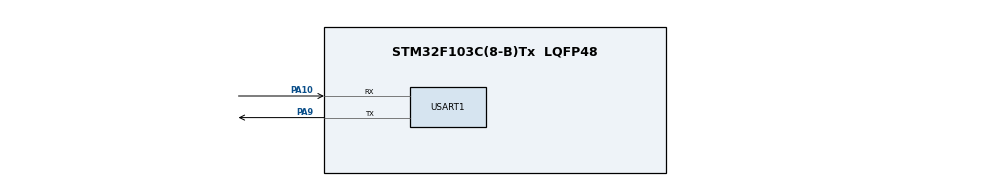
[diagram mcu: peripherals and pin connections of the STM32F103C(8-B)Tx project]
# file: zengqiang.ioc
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Mcu.Family=STM32F1
Mcu.Name=STM32F103C(8-B)Tx
Mcu.Package=LQFP48
NVIC.PriorityGroup=NVIC_PRIORITYGROUP_4
NVIC.USART1_IRQn=true\:0\:0\:false\:false\:true\:true\:true\:true
PA10.Mode=Asynchronous
PA10.Signal=USART1_RX
PA13.Mode=Serial_Wire
PA13.Signal=SYS_JTMS-SWDIO
PA14.Mode=Serial_Wire
PA14.Signal=SYS_JTCK-SWCLK
PA9.Mode=Asynchronous
PA9.Signal=USART1_TX
PD0-OSC_IN.Mode=HSE-External-Oscillator
PD0-OSC_IN.Signal=RCC_OSC_IN
PD1-OSC_OUT.Mode=HSE-External-Oscillator
PD1-OSC_OUT.Signal=RCC_OSC_OUT
ProjectManager.HeapSize=0x200
ProjectManager.StackSize=0x400
ProjectManager.TargetToolchain=MDK-ARM V5
RCC.APB1Freq_Value=8000000
RCC.APB2Freq_Value=8000000
USART1.VirtualMode=VM_ASYNC
board=custom

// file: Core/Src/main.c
/* USER CODE BEGIN Header */
/**
  ******************************************************************************
  * @file           : main.c
  * @brief          : Main program body
  ******************************************************************************
  * @attention
  *
  * Copyright (c) 2025 STMicroelectronics.
  * All rights reserved.
  *
  * This software is licensed under terms that can be found in the LICENSE file
  * in the root directory of this software component.
  * If no LICENSE file comes with this software, it is provided AS-IS.
  *
  ******************************************************************************
  */
/* USER CODE END Header */
#include "main.h"
#include "usart.h"
#include "gpio.h"

/* USER CODE BEGIN Includes */
#include <string.h>
/* USER CODE END Includes */

/* USER CODE BEGIN PD */
#define SEND_INTERVAL 500  // 发送间隔，单位ms
/* USER CODE END PD */

/* USER CODE BEGIN PV */
uint8_t send_enable = 1;  // 发送使能标志，1：允许发送，0：禁止发送
uint8_t rx_data;          // 接收缓冲区
uint8_t tx_buffer[] = "hello windows!\r\n";  // 要发送的字符串
/* USER CODE END PV */

void SystemClock_Config(void);
/* USER CODE BEGIN PFP */
void UART_Receive_Handler(void);
/* USER CODE END PFP */

/* USER CODE BEGIN 0 */
/**
  * @brief  串口接收中断处理函数
  * @param  None
  * @retval None
  */
void UART_Receive_Handler(void)
{
  // 根据接收到的字符控制发送状态
  switch(rx_data)
  {
    case '#':  // 暂停发送
      send_enable = 0;
      break;
    case '*':  // 继续发送
      send_enable = 1;
      break;
    default:   // 其他字符不处理
      break;
  }

  // 重新使能串口接收中断
  HAL_UART_Receive_IT(&huart1, &rx_data, 1);
}

/**
  * @brief  串口接收中断回调函数
  * @param  huart: 串口句柄
  * @retval None
  */
void HAL_UART_RxCpltCallback(UART_HandleTypeDef *huart)
{
  if(huart == &huart1)
  {
    UART_Receive_Handler();
  }
}
/* USER CODE END 0 */

int main(void)
{

  /* MCU Configuration--------------------------------------------------------*/

  /* Reset of all peripherals, Initializes the Flash interface and the Systick. */
  HAL_Init();

  /* Configure the system clock */
  SystemClock_Config();

  /* Initialize all configured peripherals */
  MX_GPIO_Init();
  MX_USART1_UART_Init();
  /* USER CODE BEGIN 2 */
  // 使能串口接收中断
  if(HAL_UART_Receive_IT(&huart1, &rx_data, 1) != HAL_OK)
  {
    Error_Handler();
  }
  /* USER CODE END 2 */

  /* Infinite loop */
  while (1)
  {

    /* USER CODE BEGIN 3 */
    // 如果允许发送，则定时发送字符串
    if(send_enable)
    {
      // 发送数据
      HAL_UART_Transmit(&huart1, tx_buffer, strlen((char*)tx_buffer), 0xFFFF);

      // 延时一段时间
      HAL_Delay(SEND_INTERVAL);
    }
  }
  /* USER CODE END 3 */
}

void SystemClock_Config(void)
{
  RCC_OscInitTypeDef RCC_OscInitStruct = {0};
  RCC_ClkInitTypeDef RCC_ClkInitStruct = {0};

  /** Initializes the RCC Oscillators according to the specified parameters
  * in the RCC_OscInitTypeDef structure.
  */
  RCC_OscInitStruct.OscillatorType = RCC_OSCILLATORTYPE_HSI;
  RCC_OscInitStruct.HSIState = RCC_HSI_ON;
  RCC_OscInitStruct.HSICalibrationValue = RCC_HSICALIBRATION_DEFAULT;
  RCC_OscInitStruct.PLL.PLLState = RCC_PLL_NONE;
  if (HAL_RCC_OscConfig(&RCC_OscInitStruct) != HAL_OK)
  {
    Error_Handler();
  }

  /** Initializes the CPU, AHB and APB buses clocks
  */
  RCC_ClkInitStruct.ClockType = RCC_CLOCKTYPE_HCLK|RCC_CLOCKTYPE_SYSCLK
                              |RCC_CLOCKTYPE_PCLK1|RCC_CLOCKTYPE_PCLK2;
  RCC_ClkInitStruct.SYSCLKSource = RCC_SYSCLKSOURCE_HSI;
  RCC_ClkInitStruct.AHBCLKDivider = RCC_SYSCLK_DIV1;
  RCC_ClkInitStruct.APB1CLKDivider = RCC_HCLK_DIV1;
  RCC_ClkInitStruct.APB2CLKDivider = RCC_HCLK_DIV1;

  if (HAL_RCC_ClockConfig(&RCC_ClkInitStruct, FLASH_LATENCY_0) != HAL_OK)
  {
    Error_Handler();
  }
}

void Error_Handler(void)
{
  /* USER CODE BEGIN Error_Handler_Debug */
  /* User can add his own implementation to report the HAL error return state */
  __disable_irq();
  while (1)
  {
    // 错误处理，可以添加LED闪烁等提示
  }
  /* USER CODE END Error_Handler_Debug */
}
